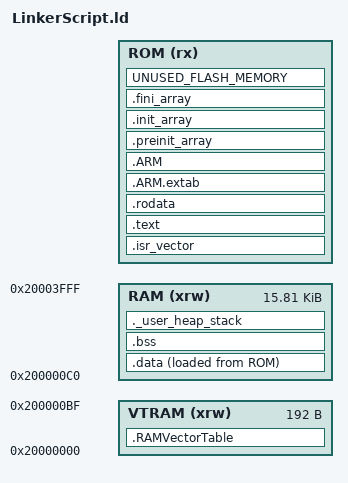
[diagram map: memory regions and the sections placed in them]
/*
******************************************************************************
** File        : LinkerScript.ld
** Author      : Auto-generated by Ac6 System Workbench,
**               modified by Aegean Associates, Inc. (AO)
** Abstract    : Linker script for STM32F070CBTx Device from STM32F0 series
**               16Kbytes RAM
**               128Kbytes ROM
**               Sets heap size, stack size and stack location according
**               to application requirements. Sets memory bank area and 
**               size if external memory is used. Also conditionally adjusts
**               the application start address and size limit to accommodate
**               an existing boot loader.
** Target      : STMicroelectronics STM32
** Distribution: Distributed "as is", without any warranty of any kind.
*****************************************************************************
** @attention
** <h2><center>&copy; COPYRIGHT(c) 2018 Ac6</center></h2>
**
** Redistribution and use in source and binary forms, with or without 
** modification, are permitted provided that the following conditions
** are met:
**   1. Redistributions of source code must retain the above copyright
**      notice, this list of conditions and the following disclaimer.
**   2. Redistributions in binary form must reproduce the above copyright
**      notice, this list of conditions and the following disclaimer in the 
**      documentation and/or other materials provided with the distribution.
**   3. Neither the name of Ac6 nor the names of its contributors may be 
**      used to endorse or promote products derived from this software
**      without specific prior written permission.
**
** THIS SOFTWARE IS PROVIDED BY THE COPYRIGHT HOLDERS AND CONTRIBUTORS 
** "AS IS" AND ANY EXPRESS OR IMPLIED WARRANTIES, INCLUDING, BUT NOT 
** LIMITED TO, THE IMPLIED WARRANTIES OF MERCHANTABILITY AND FITNESS 
** FOR A PARTICULAR PURPOSE ARE DISCLAIMED. IN NO EVENT SHALL THE 
** COPYRIGHT HOLDER OR CONTRIBUTORS BE LIABLE FOR ANY DIRECT, INDIRECT,
** INCIDENTAL, SPECIAL, EXEMPLARY, OR  CONSEQUENTIAL DAMAGES (INCLUDING,
** BUT NOT LIMITED TO, PROCUREMENT OF  SUBSTITUTE GOODS OR SERVICES; LOSS
** OF USE, DATA, OR PROFITS; OR BUSINESS  INTERRUPTION) HOWEVER CAUSED AND
** ON ANY THEORY OF LIABILITY, WHETHER IN  CONTRACT, STRICT LIABILITY, OR
** TORT (INCLUDING NEGLIGENCE OR OTHERWISE) ARISING IN ANY WAY OUT OF THE
** USE OF THIS SOFTWARE, EVEN IF ADVISED OF THE POSSIBILITY OF SUCH DAMAGE.
*****************************************************************************
*/

/* entry point */
ENTRY(Reset_Handler)

/* highest address of the user mode stack */
_estack = 0x20004000;    /* end of RAM */

/* ###AO### */
_Min_Heap_Size = 0;      /* required amount of heap  */
_Min_Stack_Size = 0x800; /* required amount of stack */

/* ###AO### */
/* adjust for memory used for the bootloader(8K) and flashstore(2K) */
_StartRom = 0x08000000 + (DEFINED(VectorTable) ? 0x2000 : 0);
_RomLen = 128K - 2K    - (DEFINED(VectorTable) ? 0x2000 : 0);
_RomTop = _StartRom + _RomLen;

/* memories definition */
MEMORY
{
/* ###AO### vector table RAM */
VTRAM (xrw)	: ORIGIN = 0x20000000, LENGTH = 0xc0
  RAM (xrw)	: ORIGIN = 0x200000c0, LENGTH = 16K - 0xc0
  ROM (rx)	: ORIGIN = _StartRom, LENGTH = _RomLen  
}

/* sections */
SECTIONS
{
  /* the startup code into ROM memory */
  .isr_vector :
  {
    . = ALIGN(4);
    KEEP(*(.isr_vector)) /* startup code */
    . = ALIGN(4);
  } >ROM

  /* the program code and other data into ROM memory */
  .text :
  {
    . = ALIGN(4);
    *(.text)           /* .text sections (code) */
    *(.text*)          /* .text* sections (code) */
    *(.glue_7)         /* glue arm to thumb code */
    *(.glue_7t)        /* glue thumb to arm code */
    *(.eh_frame)

    KEEP (*(.init))
    KEEP (*(.fini))

    . = ALIGN(4);
    _etext = .;        /* define a global symbols at end of code */
  } >ROM

  /* constant data into ROM memory*/
  .rodata :
  {
    . = ALIGN(4);
    *(.rodata)         /* .rodata sections (constants, strings, etc.) */
    *(.rodata*)        /* .rodata* sections (constants, strings, etc.) */
    . = ALIGN(4);
  } >ROM

  .ARM.extab :
  { 
    . = ALIGN(4);
    *(.ARM.extab* .gnu.linkonce.armextab.*)
    . = ALIGN(4);
  } >ROM
  
  .ARM :
  {
    . = ALIGN(4);
    __exidx_start = .;
    *(.ARM.exidx*)
    __exidx_end = .;
    . = ALIGN(4);
  } >ROM

  .preinit_array :
  {
    . = ALIGN(4);
    PROVIDE_HIDDEN (__preinit_array_start = .);
    KEEP (*(.preinit_array*))
    PROVIDE_HIDDEN (__preinit_array_end = .);
    . = ALIGN(4);
  } >ROM
  
  .init_array :
  {
    . = ALIGN(4);
    PROVIDE_HIDDEN (__init_array_start = .);
    KEEP (*(SORT(.init_array.*)))
    KEEP (*(.init_array*))
    PROVIDE_HIDDEN (__init_array_end = .);
    . = ALIGN(4);
  } >ROM
  
  .fini_array :
  {
    . = ALIGN(4);
    PROVIDE_HIDDEN (__fini_array_start = .);
    KEEP (*(SORT(.fini_array.*)))
    KEEP (*(.fini_array*))
    PROVIDE_HIDDEN (__fini_array_end = .);
    . = ALIGN(4);
  } >ROM

  /* used by the startup to initialize data */
  _sidata = LOADADDR(.data);

  /* initialized data sections into RAM memory */
  .data : 
  {
    . = ALIGN(4);
    _sdata = .;        /* create a global symbol at data start */
    *(.data)           /* .data sections */
    *(.data*)          /* .data* sections */

    . = ALIGN(4);
    _edata = .;        /* define a global symbol at data end */
  } >RAM AT> ROM

  /* ###AO### add a section to identify unused flash memory */ 
  UNUSED_FLASH_MEMORY(NOLOAD) :
  {
	. = ALIGN(1);
	. += ABSOLUTE(_RomTop) - ABSOLUTE(.);
  } > ROM
  
  /* uninitialized data section into RAM memory */
  . = ALIGN(4);
  .bss :
  {
    /* this is used by the startup in order to initialize the .bss secion */
    _sbss = .;         /* define a global symbol at bss start */
    __bss_start__ = _sbss;
    *(.bss)
    *(.bss*)
    *(COMMON)

    . = ALIGN(4);
    _ebss = .;         /* define a global symbol at bss end */
    __bss_end__ = _ebss;
  } >RAM

  /* user_heap_stack section, used to check that there is enough RAM left */
  ._user_heap_stack :
  {
    . = ALIGN(8);
    PROVIDE ( end = . );
    PROVIDE ( _end = . );
    . = . + _Min_Heap_Size;
    . = . + _Min_Stack_Size;
    . = ALIGN(8);
  } >RAM


  /* remove information from the compiler libraries */
  /DISCARD/ :
  {
    libc.a ( * )
    libm.a ( * )
    libgcc.a ( * )
  }

  .ARM.attributes 0 : { *(.ARM.attributes) }
  /* ###AO### RAM space for the vector table */
  .RAMVectorTable(NOLOAD): { *(.RAMVectorTable) } > VTRAM
}
